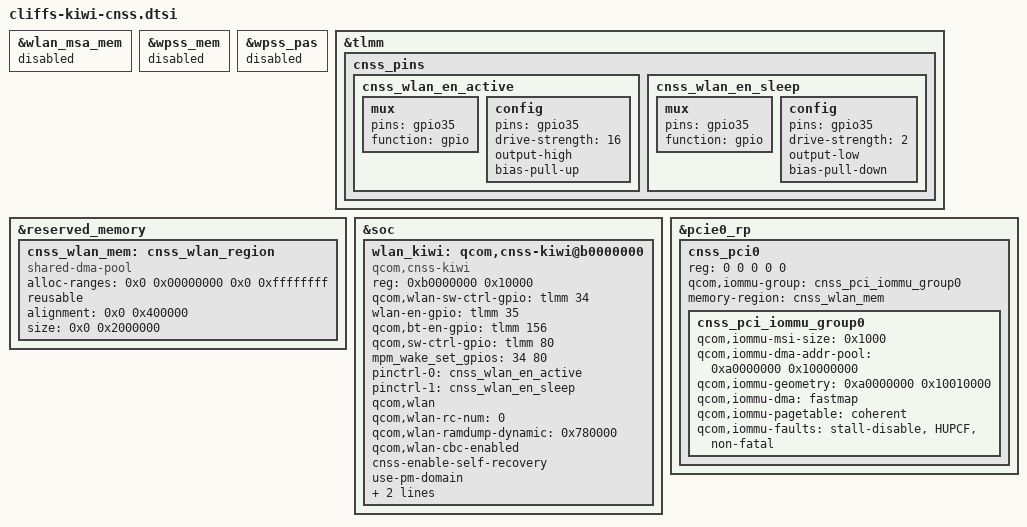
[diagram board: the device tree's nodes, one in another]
#include <dt-bindings/interconnect/qcom,cliffs.h>

&wlan_msa_mem {
	status = "disabled";
};

&wpss_mem {
	status = "disabled";
};

&wpss_pas {
	status = "disabled";
};

&tlmm {
	cnss_pins {
		cnss_wlan_en_active: cnss_wlan_en_active {
			mux {
				pins = "gpio35";
				function = "gpio";
			};

			config {
				pins = "gpio35";
				drive-strength = <16>;
				output-high;
				bias-pull-up;
			};
		};

		cnss_wlan_en_sleep: cnss_wlan_en_sleep {
			mux {
				pins = "gpio35";
				function = "gpio";
			};

			config {
				pins = "gpio35";
				drive-strength = <2>;
				output-low;
				bias-pull-down;
			};
		};
	};
};

&reserved_memory {
	cnss_wlan_mem: cnss_wlan_region {
		compatible = "shared-dma-pool";
		alloc-ranges = <0x0 0x00000000 0x0 0xffffffff>;
		reusable;
		alignment = <0x0 0x400000>;
		size = <0x0 0x2000000>;
	};
};

&soc {
	wlan_kiwi: qcom,cnss-kiwi@b0000000 {
		compatible = "qcom,cnss-kiwi";
		reg = <0xb0000000 0x10000>;
		reg-names = "smmu_iova_ipa";
		qcom,wlan-sw-ctrl-gpio = <&tlmm 34 0>;

		wlan-en-gpio = <&tlmm 35 0>;
		qcom,bt-en-gpio = <&tlmm 156 0>;
		qcom,sw-ctrl-gpio = <&tlmm 80 0>;
		/* List of GPIOs to be setup for interrupt wakeup capable */
		mpm_wake_set_gpios = <34 80>;
		pinctrl-names = "wlan_en_active", "wlan_en_sleep";
		pinctrl-0 = <&cnss_wlan_en_active>;
		pinctrl-1 = <&cnss_wlan_en_sleep>;
		qcom,wlan;
		qcom,wlan-rc-num = <0>;
		qcom,wlan-ramdump-dynamic = <0x780000>;
		qcom,wlan-cbc-enabled;
		cnss-enable-self-recovery;
		use-pm-domain;
		qcom,same-dt-multi-dev;
		/* For AOP communication, use direct QMP instead of mailbox */
		qcom,qmp = <&aoss_qmp>;
	};
};

&pcie0_rp {
	#address-cells = <5>;
	#size-cells = <0>;

	cnss_pci0: cnss_pci0 {
		reg = <0 0 0 0 0>;
		qcom,iommu-group = <&cnss_pci_iommu_group0>;
		memory-region = <&cnss_wlan_mem>;

		#address-cells = <1>;
		#size-cells = <1>;

		cnss_pci_iommu_group0: cnss_pci_iommu_group0 {
			qcom,iommu-msi-size = <0x1000>;
			qcom,iommu-dma-addr-pool = <0xa0000000 0x10000000>;
			qcom,iommu-geometry = <0xa0000000 0x10010000>;
			qcom,iommu-dma = "fastmap";
			qcom,iommu-pagetable = "coherent";
			qcom,iommu-faults = "stall-disable", "HUPCF", "non-fatal";
		};
	};
};
